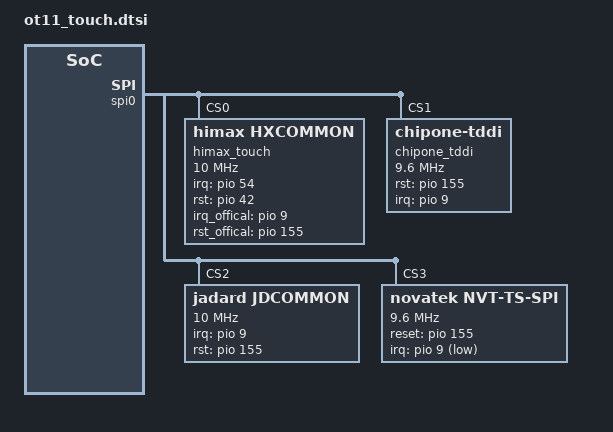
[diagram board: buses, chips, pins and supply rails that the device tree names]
// SPDX-License-Identifier: (GPL-2.0 OR MIT)
/*
 * Copyright (C) 2020 MediaTek Inc.
 */

/* TOUCH start */
/*Tab A9 code for AX6739A-6 by wenghailong at 20230418 start*/
&spi0 {
    status = "okay";
    #address-cells = <1>;
    #size-cells = <0>;
    mediatek,pad-select = <0>;
    cs-gpios = <0>, <0>, <0>, <0>;

    himax_touch@0 {
        compatible = "himax,hxcommon";
        reg = <0>;
        status = "okay";
        spi-max-frequency = <10000000>;
        spi-cpha;
        interrupt-parent = <&pio>;
        himax,panel-coords = <0 800 0 1340>;
        himax,display-coords = <0 800 0 1340>;
        himax,irq-gpio = <&pio 54 0x00>;
        himax,rst-gpio = <&pio 42 0x00>;
        /*Tab A9 code for SR-AX6739A-01-282 by wenghailong at 20230502 start*/
        himax,irq_offical-gpio = <&pio 9 0x00>;
        himax,rst_offical-gpio = <&pio 155 0x00>;
        /*Tab A9 code for SR-AX6739A-01-282 by wenghailong at 20230502 end*/
        report_type = <1>;
    };
    /*Tab A9 code for SR-AX6739A-01-713 by suyurui at 20230601 start*/
    chipone_tddi@1 {
        compatible = "chipone-tddi";
        reg = <1>;
        spi-max-frequency = <9600000>;
        interrupt-parent = <&pio>;
        interrupts = <9 0x2008>;
        chipone,rst-gpio = <&pio 155 0x00>;
        chipone,irq-gpio = <&pio 9 0x00>;
        //chipone,cs-gpio = <&pio 8 0>;
        chipone,x-res = <800>;
        chipone,y-res = <1340>;

        /* Charger detect */
        chipone,touch-charger-detect-enable;
        chipone,touch-charger-detect-type = "notify"; /* notify, poll */
        chipone,touch-charger-detect-psy-name = "charger";
        chipone,touch-charger-detect-psp = "POWER_SUPPLY_PROP_ONLINE";
        chipone,touch-charger-detect-psp-poll-interval = <1000>;

        /* Earjack detect */
        chipone,touch-earjack-detect-enable;
        /* MTK:  /sys/bus/platform/drivers/Accdet_Driver/state,
           Sprd: /sys/kernel/headset/state
           QCOM: None, and disable it */
        chipone,touch-earjack-state-filepath = "/sys/bus/platform/drivers/Accdet_Driver/state";
        chipone,touch-earjack-poll-interval = <1000>;

        /*Tab A9 code for AX6739A-961 by suyurui at 20230609 start*/
        /* For tp selftest */
        chipone,test-reset-pin;
        //chipone,test-int-pin;
        chipone,test-rawdata;
        chipone,test-rawdata-frames = <1>;
        chipone,rawdata-min = <1222>;
        chipone,rawdata-max = <2862>;
        chipone,test-noise;
        chipone,test-noise-frames = <50>;
        chipone,noise-max = <130>;
        chipone,test-open;
        chipone,open-min = <2100>;
        chipone,test-short;
        chipone,short-min = <1900>;
        chipone,test-compensate-cap;
        chipone,compensate-cap-min = <1>;
        chipone,compensate-cap-max = <127>;
        /*Tab A9 code for AX6739A-961 by suyurui at 20230609 end*/

    };
    /*Tab A9 code for SR-AX6739A-01-713 by suyurui at 20230601 end*/

    /*Tab A9 code for SR-AX6739A-01-715 by hehaoran5 at 20230609 start*/
    jadard@2 {
        compatible = "jadard,jdcommon";
        reg = <2>;
        status = "okay";
        spi-max-frequency = <10000000>;//10M
        interrupt-parent = <&pio>;
        interrupts = <9 0x00>;
        jadard,panel-sense-nums = <22 36>;
        jadard,panel-coords = <0 800 0 1340>;
        jadard,int-is-edge = <1>;
        jadard,panel-max-points = <10>;
        jadard,irq-gpio = <&pio 9 0x00>;
        jadard,rst-gpio = <&pio 155 0x00>;
    };
    /*Tab A9 code for SR-AX6739A-01-715 by hehaoran5 at 20230609 end*/

    /*Tab A9 code for AX6739A-2660 by zhawei at 20230811 start*/
    /* Novatek device tree node */
    novatek@3 {
        compatible = "novatek,NVT-ts-spi";
        reg = <3>; //Same as CS ID
        status = "ok";

        spi-max-frequency = <9600000>;    //4800000,9600000,15000000,19200000
        novatek,reset-gpio = <&pio 155 0x00>;
        novatek,irq-gpio = <&pio 9 0x2001>;

        /* 525 */
        //novatek,swrst-n8-addr = <0x01F01A>;

        /* 672A, 525B, 675, 526, 672C, 523, 528, 523D */
        novatek,swrst-n8-addr = <0x03F0FE>;
        novatek,spi-rd-fast-addr = <0x03F310>;

        /*Panel setting*/
        novatek,resolution = <800 1340>;
        novatek,max_touch_num = <10>;
        novatek,area-size = <56 112 60>;    //indicator navigation edge
        novatek,fw_name = "novatek_ts_fw.bin", "tsp_novatek/OT11_NT36523D_LC_HSD_FW_V001_2023xxxx.bin";
        novatek,fw_name_mp = "novatek_ts_mp.bin", "tsp_novatek/OT11_NT36523D_LC_HSD_MP_V001_2023xxxx.bin ";
        //novatek,support_ear_detect_mode;
        novatek,enable_settings_aot;

        /* MP */
        novatek,mp-support-dt;

        novatek-mp-criteria-725E@0 {
            #address-cells = <1>;
            #size-cells = <0>;
            compatible = "novatek-mp-criteria-725E";

            /* sec cmd test config */
            open_test_spec = <(-511) 5120>;
            short_test_spec = <10000 14008>;
            diff_test_frame = <50>;
            /* sec cmd fdm test config */
            fdm_x_num = <2>;
            fdm_diff_test_frame = <50>;

            /* MP Config */
            IC_X_CFG_SIZE = <22>;
            IC_Y_CFG_SIZE = <36>;
            IC_KEY_CFG_SIZE = <4>;
            X_Channel = <22>;
            Y_Channel = <36>;
            AIN_X = <0 1 2 3 4 5 6 7 8 9 10 11 12 13 14 15 16 17 18 19 20 21>; // 22 23 24 25 26 27 28 29 30 31>;
            AIN_Y = <0 1 2 3 4 5 6 7 8 9 10 11 12 13 14 15 16 17
                        18 19 20 21 22 23 24 25 26 27 28 29 30 31 32 33 34 35>; // 36 37 38 39
                        //40 41 42 43 44 45 46 47 48 49>;
            AIN_KEY = <0 1 2 0xFF 0xFF 0xFF 0xFF 0xFF>;

            /* MP Criteria */
            PS_Config_Lmt_Short_Rawdata_P = <
                14008 14008 14008 14008 14008 14008 14008 14008 14008 14008 14008 14008 14008 14008 14008 14008 14008 14008 14008 14008 14008 14008
                14008 14008 14008 14008 14008 14008 14008 14008 14008 14008 14008 14008 14008 14008 14008 14008 14008 14008 14008 14008 14008 14008
                14008 14008 14008 14008 14008 14008 14008 14008 14008 14008 14008 14008 14008 14008 14008 14008 14008 14008 14008 14008 14008 14008
                14008 14008 14008 14008 14008 14008 14008 14008 14008 14008 14008 14008 14008 14008 14008 14008 14008 14008 14008 14008 14008 14008
                14008 14008 14008 14008 14008 14008 14008 14008 14008 14008 14008 14008 14008 14008 14008 14008 14008 14008 14008 14008 14008 14008
                14008 14008 14008 14008 14008 14008 14008 14008 14008 14008 14008 14008 14008 14008 14008 14008 14008 14008 14008 14008 14008 14008
                14008 14008 14008 14008 14008 14008 14008 14008 14008 14008 14008 14008 14008 14008 14008 14008 14008 14008 14008 14008 14008 14008
                14008 14008 14008 14008 14008 14008 14008 14008 14008 14008 14008 14008 14008 14008 14008 14008 14008 14008 14008 14008 14008 14008
                14008 14008 14008 14008 14008 14008 14008 14008 14008 14008 14008 14008 14008 14008 14008 14008 14008 14008 14008 14008 14008 14008
                14008 14008 14008 14008 14008 14008 14008 14008 14008 14008 14008 14008 14008 14008 14008 14008 14008 14008 14008 14008 14008 14008
                14008 14008 14008 14008 14008 14008 14008 14008 14008 14008 14008 14008 14008 14008 14008 14008 14008 14008 14008 14008 14008 14008
                14008 14008 14008 14008 14008 14008 14008 14008 14008 14008 14008 14008 14008 14008 14008 14008 14008 14008 14008 14008 14008 14008
                14008 14008 14008 14008 14008 14008 14008 14008 14008 14008 14008 14008 14008 14008 14008 14008 14008 14008 14008 14008 14008 14008
                14008 14008 14008 14008 14008 14008 14008 14008 14008 14008 14008 14008 14008 14008 14008 14008 14008 14008 14008 14008 14008 14008
                14008 14008 14008 14008 14008 14008 14008 14008 14008 14008 14008 14008 14008 14008 14008 14008 14008 14008 14008 14008 14008 14008
                14008 14008 14008 14008 14008 14008 14008 14008 14008 14008 14008 14008 14008 14008 14008 14008 14008 14008 14008 14008 14008 14008
                14008 14008 14008 14008 14008 14008 14008 14008 14008 14008 14008 14008 14008 14008 14008 14008 14008 14008 14008 14008 14008 14008
                14008 14008 14008 14008 14008 14008 14008 14008 14008 14008 14008 14008 14008 14008 14008 14008 14008 14008 14008 14008 14008 14008
                14008 14008 14008 14008 14008 14008 14008 14008 14008 14008 14008 14008 14008 14008 14008 14008 14008 14008 14008 14008 14008 14008
                14008 14008 14008 14008 14008 14008 14008 14008 14008 14008 14008 14008 14008 14008 14008 14008 14008 14008 14008 14008 14008 14008
                14008 14008 14008 14008 14008 14008 14008 14008 14008 14008 14008 14008 14008 14008 14008 14008 14008 14008 14008 14008 14008 14008
                14008 14008 14008 14008 14008 14008 14008 14008 14008 14008 14008 14008 14008 14008 14008 14008 14008 14008 14008 14008 14008 14008
                14008 14008 14008 14008 14008 14008 14008 14008 14008 14008 14008 14008 14008 14008 14008 14008 14008 14008 14008 14008 14008 14008
                14008 14008 14008 14008 14008 14008 14008 14008 14008 14008 14008 14008 14008 14008 14008 14008 14008 14008 14008 14008 14008 14008
                14008 14008 14008 14008 14008 14008 14008 14008 14008 14008 14008 14008 14008 14008 14008 14008 14008 14008 14008 14008 14008 14008
                14008 14008 14008 14008 14008 14008 14008 14008 14008 14008 14008 14008 14008 14008 14008 14008 14008 14008 14008 14008 14008 14008
                14008 14008 14008 14008 14008 14008 14008 14008 14008 14008 14008 14008 14008 14008 14008 14008 14008 14008 14008 14008 14008 14008
                14008 14008 14008 14008 14008 14008 14008 14008 14008 14008 14008 14008 14008 14008 14008 14008 14008 14008 14008 14008 14008 14008
                14008 14008 14008 14008 14008 14008 14008 14008 14008 14008 14008 14008 14008 14008 14008 14008 14008 14008 14008 14008 14008 14008
                14008 14008 14008 14008 14008 14008 14008 14008 14008 14008 14008 14008 14008 14008 14008 14008 14008 14008 14008 14008 14008 14008
                14008 14008 14008 14008 14008 14008 14008 14008 14008 14008 14008 14008 14008 14008 14008 14008 14008 14008 14008 14008 14008 14008
                14008 14008 14008 14008 14008 14008 14008 14008 14008 14008 14008 14008 14008 14008 14008 14008 14008 14008 14008 14008 14008 14008
                14008 14008 14008 14008 14008 14008 14008 14008 14008 14008 14008 14008 14008 14008 14008 14008 14008 14008 14008 14008 14008 14008
                14008 14008 14008 14008 14008 14008 14008 14008 14008 14008 14008 14008 14008 14008 14008 14008 14008 14008 14008 14008 14008 14008
                14008 14008 14008 14008 14008 14008 14008 14008 14008 14008 14008 14008 14008 14008 14008 14008 14008 14008 14008 14008 14008 14008
                14008 14008 14008 14008 14008 14008 14008 14008 14008 14008 14008 14008 14008 14008 14008 14008 14008 14008 14008 14008 14008 14008
                14008 14008 14008>;

            PS_Config_Lmt_Short_Rawdata_N = <
                10100    10100    10100    10100    10100    10100    10100    10100    10100    10100    10100    10100    10100    10100    10100    10100    10100    10100    10100    10100    10100    10100
                10100    10100    10100    10100    10100    10100    10100    10100    10100    10100    10100    10100    10100    10100    10100    10100    10100    10100    10100    10100    10100    10100
                10100    10100    10100    10100    10100    10100    10100    10100    10100    10100    10100    10100    10100    10100    10100    10100    10100    10100    10100    10100    10100    10100
                10100    10100    10100    10100    10100    10100    10100    10100    10100    10100    10100    10100    10100    10100    10100    10100    10100    10100    10100    10100    10100    10100
                10100    10100    10100    10100    10100    10100    10100    10100    10100    10100    10100    10100    10100    10100    10100    10100    10100    10100    10100    10100    10100    10100
                10100    10100    10100    10100    10100    10100    10100    10100    10100    10100    10100    10100    10100    10100    10100    10100    10100    10100    10100    10100    10100    10100
                10100    10100    10100    10100    10100    10100    10100    10100    10100    10100    10100    10100    10100    10100    10100    10100    10100    10100    10100    10100    10100    10100
                10100    10100    10100    10100    10100    10100    10100    10100    10100    10100    10100    10100    10100    10100    10100    10100    10100    10100    10100    10100    10100    10100
                10100    10100    10100    10100    10100    10100    10100    10100    10100    10100    10100    10100    10100    10100    10100    10100    10100    10100    10100    10100    10100    10100
                10100    10100    10100    10100    10100    10100    10100    10100    10100    10100    10100    10100    10100    10100    10100    10100    10100    10100    10100    10100    10100    10100
                10100    10100    10100    10100    10100    10100    10100    10100    10100    10100    10100    10100    10100    10100    10100    10100    10100    10100    10100    10100    10100    10100
                10100    10100    10100    10100    10100    10100    10100    10100    10100    10100    10100    10100    10100    10100    10100    10100    10100    10100    10100    10100    10100    10100
                10100    10100    10100    10100    10100    10100    10100    10100    10100    10100    10100    10100    10100    10100    10100    10100    10100    10100    10100    10100    10100    10100
                10100    10100    10100    10100    10100    10100    10100    10100    10100    10100    10100    10100    10100    10100    10100    10100    10100    10100    10100    10100    10100    10100
                10100    10100    10100    10100    10100    10100    10100    10100    10100    10100    10100    10100    10100    10100    10100    10100    10100    10100    10100    10100    10100    10100
                10100    10100    10100    10100    10100    10100    10100    10100    10100    10100    10100    10100    10100    10100    10100    10100    10100    10100    10100    10100    10100    10100
                10100    10100    10100    10100    10100    10100    10100    10100    10100    10100    10100    10100    10100    10100    10100    10100    10100    10100    10100    10100    10100    10100
                10100    10100    10100    10100    10100    10100    10100    10100    10100    10100    10100    10100    10100    10100    10100    10100    10100    10100    10100    10100    10100    10100
                10100    10100    10100    10100    10100    10100    10100    10100    10100    10100    10100    10100    10100    10100    10100    10100    10100    10100    10100    10100    10100    10100
                10100    10100    10100    10100    10100    10100    10100    10100    10100    10100    10100    10100    10100    10100    10100    10100    10100    10100    10100    10100    10100    10100
                10100    10100    10100    10100    10100    10100    10100    10100    10100    10100    10100    10100    10100    10100    10100    10100    10100    10100    10100    10100    10100    10100
                10100    10100    10100    10100    10100    10100    10100    10100    10100    10100    10100    10100    10100    10100    10100    10100    10100    10100    10100    10100    10100    10100
                10100    10100    10100    10100    10100    10100    10100    10100    10100    10100    10100    10100    10100    10100    10100    10100    10100    10100    10100    10100    10100    10100
                10100    10100    10100    10100    10100    10100    10100    10100    10100    10100    10100    10100    10100    10100    10100    10100    10100    10100    10100    10100    10100    10100
                10100    10100    10100    10100    10100    10100    10100    10100    10100    10100    10100    10100    10100    10100    10100    10100    10100    10100    10100    10100    10100    10100
                10100    10100    10100    10100    10100    10100    10100    10100    10100    10100    10100    10100    10100    10100    10100    10100    10100    10100    10100    10100    10100    10100
                10100    10100    10100    10100    10100    10100    10100    10100    10100    10100    10100    10100    10100    10100    10100    10100    10100    10100    10100    10100    10100    10100
                10100    10100    10100    10100    10100    10100    10100    10100    10100    10100    10100    10100    10100    10100    10100    10100    10100    10100    10100    10100    10100    10100
                10100    10100    10100    10100    10100    10100    10100    10100    10100    10100    10100    10100    10100    10100    10100    10100    10100    10100    10100    10100    10100    10100
                10100    10100    10100    10100    10100    10100    10100    10100    10100    10100    10100    10100    10100    10100    10100    10100    10100    10100    10100    10100    10100    10100
                10100    10100    10100    10100    10100    10100    10100    10100    10100    10100    10100    10100    10100    10100    10100    10100    10100    10100    10100    10100    10100    10100
                10100    10100    10100    10100    10100    10100    10100    10100    10100    10100    10100    10100    10100    10100    10100    10100    10100    10100    10100    10100    10100    10100
                10100    10100    10100    10100    10100    10100    10100    10100    10100    10100    10100    10100    10100    10100    10100    10100    10100    10100    10100    10100    10100    10100
                10100    10100    10100    10100    10100    10100    10100    10100    10100    10100    10100    10100    10100    10100    10100    10100    10100    10100    10100    10100    10100    10100
                10100    10100    10100    10100    10100    10100    10100    10100    10100    10100    10100    10100    10100    10100    10100    10100    10100    10100    10100    10100    10100    10100
                10100    10100    10100    10100    10100    10100    10100    10100    10100    10100    10100    10100    10100    10100    10100    10100    10100    10100    10100    10100    10100    10100
                10000 10000 10000>;

            PS_Config_Lmt_Open_Rawdata_P = <
                2328    2321    2366    2373    2423    2411    2346    2359    2297    2313    2478    2324    2356    2345    2334    2369    2362    2330    2323    2310    2290    2612
                2388    2295    2398    2426    2397    2391    2342    2328    2320    2345    2514    2299    2342    2349    2374    2362    2356    2349    2321    2327    2324    2582
                2379    2317    2415    2429    2447    2426    2372    2348    2346    2310    2503    2310    2400    2386    2380    2377    2384    2345    2339    2352    2309    2617
                2439    2335    2411    2451    2456    2394    2384    2351    2351    2374    2576    2324    2376    2395    2401    2401    2383    2401    2367    2355    2367    2626
                2429    2359    2355    2467    2461    2460    2450    2404    2426    2372    2577    2345    2355    2442    2422    2409    2437    2429    2390    2388    2386    2643
                2489    2412    2338    2496    2531    2451    2444    2409    2400    2398    2628    2394    2339    2443    2442    2456    2440    2433    2419    2400    2401    2695
                2464    2416    2369    2519    2534    2499    2484    2442    2430    2437    2598    2387    2356    2503    2482    2468    2456    2463    2421    2415    2439    2668
                2520    2475    2388    2524    2559    2512    2457    2454    2433    2444    2660    2432    2374    2485    2489    2492    2491    2465    2474    2451    2437    2727
                2521    2477    2414    2415    2575    2526    2526    2526    2482    2523    2654    2460    2397    2418    2545    2519    2498    2519    2510    2477    2471    2740
                2547    2534    2468    2397    2611    2598    2527    2535    2498    2499    2691    2482    2454    2400    2551    2541    2548    2527    2516    2507    2488    2765
                2589    2517    2482    2439    2639    2611    2576    2575    2528    2531    2731    2530    2449    2416    2607    2580    2561    2541    2540    2512    2493    2801
                2593    2572    2535    2461    2646    2647    2587    2554    2551    2538    2734    2524    2498    2433    2594    2586    2590    2579    2554    2559    2537    2785
                2659    2584    2549    2492    2486    2666    2605    2607    2626    2583    2815    2563    2526    2472    2492    2652    2610    2593    2608    2593    2551    2831
                2642    2607    2600    2538    2470    2699    2670    2617    2624    2600    2787    2573    2542    2519    2475    2646    2633    2640    2608    2597    2576    2845
                2656    2638    2580    2554    2509    2737    2689    2649    2660    2625    2804    2584    2589    2512    2493    2709    2668    2643    2619    2612    2570    2841
                2668    2639    2633    2604    2524    2744    2717    2668    2640    2643    2808    2617    2582    2555    2498    2685    2674    2675    2657    2625    2605    2887
                2692    2703    2643    2618    2554    2555    2727    2689    2684    2716    2856    2654    2621    2579    2540    2559    2738    2691    2670    2668    2610    2899
                2698    2678    2664    2661    2597    2528    2768    2747    2703    2708    2871    2688    2625    2598    2584    2541    2731    2713    2719    2666    2615    2932
                2730    2698    2708    2640    2610    2572    2799    2768    2724    2748    2898    2670    2640    2647    2575    2565    2789    2754    2723    2667    2632    2919
                2754    2699    2705    2695    2664    2580    2817    2796    2757    2731    2913    2712    2670    2640    2622    2572    2766    2759    2755    2710    2647    2974
                2822    2724    2782    2710    2681    2615    2614    2800    2778    2776    2968    2751    2701    2671    2645    2611    2631    2821    2766    2712    2689    2974
                2813    2731    2757    2731    2730    2657    2593    2845    2828    2792    2961    2751    2740    2682    2668    2656    2617    2814    2783    2759    2694    2972
                2853    2748    2780    2773    2705    2664    2628    2874    2846    2807    3013    2794    2724    2695    2713    2646    2638    2874    2818    2755    2691    3007
                2825    2772    2787    2772    2762    2733    2643    2895    2870    2845    2995    2803    2766    2727    2710    2692    2642    2846    2822    2790    2733    3013
                2873    2832    2842    2849    2773    2737    2678    2670    2880    2866    3035    2843    2807    2761    2724    2710    2684    2702    2874    2785    2729    3063
                2880    2815    2843    2820    2800    2792    2720    2646    2919    2908    3044    2835    2800    2799    2745    2734    2727    2689    2859    2799    2775    3066
                2905    2852    2866    2831    2828    2755    2712    2674    2943    2919    3048    2850    2835    2780    2754    2773    2715    2706    2904    2834    2775    3060
                2939    2817    2884    2836    2829    2814    2778    2687    2950    2934    3083    2885    2839    2808    2779    2769    2762    2708    2873    2829    2801    3101
                2967    2901    2976    2940    2946    2871    2828    2762    2748    3000    3161    2951    2941    2898    2856    2820    2813    2790    2803    2922    2838    3142
                3041    2906    2965    2933    2916    2883    2874    2811    2724    3044    3196    2982    2926    2885    2892    2845    2831    2834    2796    2905    2852    3195
                3052    2936    3004    2978    2940    2926    2859    2806    2750    3059    3213    2996    2948    2937    2884    2867    2878    2821    2815    2967    2885    3195
                3087    2974    2989    3007    2951    2932    2909    2870    2775    3077    3234    3030    2990    2940    2916    2898    2884    2880    2831    2944    2895    3235
                3104    2964    3032    3066    3004    3004    2926    2876    2803    2951    3248    3025    3004    2996    2971    2930    2894    2895    2870    2887    2947    3234
                3150    3035    3039    3052    3002    2982    2943    2919    2853    2936    3294    3058    3042    2995    2971    2978    2934    2912    2918    2884    2932    3245
                3171    3045    3066    3098    3049    3000    2975    2906    2848    2950    3300    3104    3051    3004    2999    2964    2946    2960    2902    2905    2990    3291
                3179    3076    3093    3069    3065    3007    2976    2967    2943    3032    3279    3062    3074    3046    3021    3013    2995    2978    2971    2937    2981    3298
                5120 5120 5120>;

            PS_Config_Lmt_Open_Rawdata_N = <
                998    995    1014    1017    1039    1033    1006    1011    985    991    1062    996    1010    1005    1000    1015    1012    998    995    990    982    1120
                1024    983    1028    1040    1027    1025    1004    998    994    1005    1078    985    1004    1007    1018    1012    1010    1007    995    997    996    1106
                1019    993    1035    1041    1049    1040    1016    1006    1006    990    1073    990    1028    1022    1020    1019    1022    1005    1003    1008    989    1121
                1045    1001    1033    1051    1052    1026    1022    1007    1007    1018    1104    996    1018    1027    1029    1029    1021    1029    1015    1009    1015    1126
                1041    1011    1009    1057    1055    1054    1050    1030    1040    1016    1105    1005    1009    1046    1038    1033    1045    1041    1024    1024    1022    1133
                1067    1034    1002    1070    1085    1051    1048    1033    1028    1028    1126    1026    1003    1047    1046    1052    1046    1043    1037    1028    1029    1155
                1056    1036    1015    1079    1086    1071    1064    1046    1042    1045    1114    1023    1010    1073    1064    1058    1052    1055    1037    1035    1045    1144
                1080    1061    1024    1082    1097    1076    1053    1052    1043    1048    1140    1042    1018    1065    1067    1068    1067    1057    1060    1051    1045    1169
                1081    1061    1034    1035    1103    1082    1082    1082    1064    1081    1138    1054    1027    1036    1091    1079    1070    1079    1076    1061    1059    1174
                1091    1086    1058    1027    1119    1114    1083    1087    1070    1071    1153    1064    1052    1028    1093    1089    1092    1083    1078    1075    1066    1185
                1109    1079    1064    1045    1131    1119    1104    1103    1084    1085    1171    1084    1049    1036    1117    1106    1097    1089    1088    1076    1069    1201
                1111    1102    1087    1055    1134    1135    1109    1094    1093    1088    1172    1082    1070    1043    1112    1108    1110    1105    1094    1097    1087    1193
                1139    1108    1093    1068    1066    1142    1117    1117    1126    1107    1207    1099    1082    1060    1068    1136    1118    1111    1118    1111    1093    1213
                1132    1117    1114    1088    1058    1157    1144    1121    1124    1114    1195    1103    1090    1079    1061    1134    1129    1132    1118    1113    1104    1219
                1138    1130    1106    1094    1075    1173    1153    1135    1140    1125    1202    1108    1109    1076    1069    1161    1144    1133    1123    1120    1102    1217
                1144    1131    1129    1116    1082    1176    1165    1144    1132    1133    1204    1121    1106    1095    1070    1151    1146    1147    1139    1125    1117    1237
                1154    1159    1133    1122    1094    1095    1169    1153    1150    1164    1224    1138    1123    1105    1088    1097    1174    1153    1144    1144    1118    1243
                1156    1148    1142    1141    1113    1084    1186    1177    1159    1160    1231    1152    1125    1114    1108    1089    1171    1163    1165    1142    1121    1256
                1170    1156    1160    1132    1118    1102    1199    1186    1168    1178    1242    1144    1132    1135    1103    1099    1195    1180    1167    1143    1128    1251
                1180    1157    1159    1155    1142    1106    1207    1198    1181    1171    1249    1162    1144    1132    1124    1102    1186    1183    1181    1162    1135    1274
                1210    1168    1192    1162    1149    1121    1120    1200    1190    1190    1272    1179    1157    1145    1133    1119    1127    1209    1186    1162    1153    1274
                1205    1171    1181    1171    1170    1139    1111    1219    1212    1196    1269    1179    1174    1150    1144    1138    1121    1206    1193    1183    1154    1274
                1223    1178    1192    1189    1159    1142    1126    1232    1220    1203    1291    1198    1168    1155    1163    1134    1130    1232    1208    1181    1153    1289
                1211    1188    1195    1188    1184    1171    1133    1241    1230    1219    1283    1201    1186    1169    1162    1154    1132    1220    1210    1196    1171    1291
                1231    1214    1218    1221    1189    1173    1148    1144    1234    1228    1301    1219    1203    1183    1168    1162    1150    1158    1232    1193    1169    1313
                1234    1207    1219    1208    1200    1196    1166    1134    1251    1246    1304    1215    1200    1199    1177    1172    1169    1153    1225    1199    1189    1314
                1245    1222    1228    1213    1212    1181    1162    1146    1261    1251    1306    1222    1215    1192    1180    1189    1163    1160    1244    1214    1189    1312
                1259    1207    1236    1216    1213    1206    1190    1151    1264    1258    1321    1237    1217    1204    1191    1187    1184    1160    1231    1213    1201    1329
                1271    1243    1276    1260    1262    1231    1212    1184    1178    1286    1355    1265    1261    1242    1224    1208    1205    1196    1201    1252    1216    1346
                1303    1246    1271    1257    1250    1235    1232    1205    1168    1304    1370    1278    1254    1237    1240    1219    1213    1214    1198    1245    1222    1369
                1308    1258    1288    1276    1260    1254    1225    1202    1178    1311    1377    1284    1264    1259    1236    1229    1234    1209    1207    1271    1237    1369
                1323    1274    1281    1289    1265    1256    1247    1230    1189    1319    1386    1298    1282    1260    1250    1242    1236    1234    1213    1262    1241    1387
                1330    1270    1300    1314    1288    1288    1254    1232    1201    1265    1392    1297    1288    1284    1273    1256    1240    1241    1230    1237    1263    1386
                1350    1301    1303    1308    1286    1278    1261    1251    1223    1258    1412    1310    1304    1283    1273    1276    1258    1248    1250    1236    1256    1391
                1359    1305    1314    1328    1307    1286    1275    1246    1220    1264    1414    1330    1307    1288    1285    1270    1262    1268    1244    1245    1282    1411
                1363    1318    1325    1315    1313    1289    1276    1271    1261    1300    1405    1312    1318    1306    1295    1291    1283    1276    1273    1259    1277    1414
                (-511) (-511) (-511)>;

            PS_Config_Lmt_FW_Rawdata_P = <
                1120    1102    1107    1120    1116    1134    1114    1110    1121    1121    1133    1121    1113    1109    1127    1121    1124    1113    1134    1112    1124    1138
                1114    1105    1124    1116    1127    1123    1134    1114    1137    1113    1133    1131    1119    1126    1120    1114    1130    1119    1110    1121    1124    1127
                1112    1130    1114    1110    1116    1120    1117    1103    1112    1109    1127    1113    1114    1126    1128    1106    1114    1112    1123    1120    1113    1120
                1114    1117    1110    1105    1113    1124    1119    1112    1117    1119    1116    1117    1123    1117    1123    1116    1113    1121    1103    1117    1117    1109
                1113    1106    1120    1131    1102    1130    1127    1120    1121    1140    1112    1119    1107    1120    1130    1114    1133    1109    1120    1109    1114    1127
                1116    1112    1120    1121    1116    1128    1123    1117    1114    1117    1119    1130    1112    1106    1124    1110    1110    1134    1126    1124    1114    1121
                1123    1114    1107    1114    1106    1116    1130    1112    1119    1114    1113    1124    1112    1112    1121    1119    1117    1113    1123    1106    1114    1119
                1112    1120    1119    1107    1114    1119    1116    1127    1117    1113    1123    1121    1114    1124    1120    1116    1120    1128    1114    1135    1124    1109
                1128    1117    1121    1119    1123    1114    1131    1119    1124    1126    1131    1128    1116    1133    1119    1114    1114    1102    1114    1116    1128    1123
                1105    1112    1131    1116    1123    1121    1131    1107    1113    1112    1119    1121    1113    1113    1124    1123    1127    1121    1123    1120    1112    1109
                1120    1112    1123    1134    1113    1120    1124    1106    1133    1127    1116    1116    1119    1121    1121    1123    1117    1116    1112    1133    1117    1123
                1141    1113    1106    1113    1128    1114    1119    1121    1116    1112    1127    1119    1126    1120    1109    1124    1114    1123    1124    1110    1113    1114
                1128    1134    1120    1130    1112    1121    1121    1119    1112    1105    1107    1110    1119    1116    1124    1116    1121    1110    1116    1119    1119    1109
                1112    1124    1120    1107    1106    1114    1121    1134    1120    1112    1140    1117    1131    1112    1109    1123    1121    1127    1112    1123    1116    1128
                1140    1112    1137    1134    1121    1117    1110    1121    1130    1110    1112    1124    1112    1106    1113    1107    1110    1116    1119    1112    1123    1117
                1110    1133    1120    1126    1114    1113    1119    1121    1114    1127    1126    1113    1103    1107    1123    1117    1131    1112    1127    1120    1105    1127
                1124    1124    1116    1113    1109    1120    1144    1123    1127    1109    1130    1116    1117    1116    1140    1113    1119    1121    1114    1121    1119    1134
                1119    1107    1116    1124    1126    1126    1112    1124    1127    1128    1116    1123    1117    1128    1123    1112    1107    1107    1100    1106    1127    1124
                1119    1121    1127    1119    1112    1120    1124    1107    1131    1116    1123    1121    1135    1126    1121    1110    1116    1116    1113    1124    1112    1126
                1142    1114    1112    1110    1116    1121    1130    1119    1117    1116    1121    1128    1117    1120    1126    1127    1127    1109    1121    1123    1130    1116
                1130    1117    1105    1113    1123    1123    1114    1124    1128    1119    1134    1126    1126    1128    1110    1119    1113    1119    1113    1114    1119    1133
                1109    1117    1137    1119    1110    1124    1110    1126    1116    1116    1110    1137    1117    1113    1126    1130    1123    1116    1117    1093    1110    1131
                1106    1126    1106    1109    1127    1117    1117    1106    1128    1112    1123    1128    1120    1105    1119    1121    1121    1124    1121    1117    1119    1106
                1128    1138    1123    1120    1131    1109    1123    1107    1124    1131    1117    1131    1109    1117    1131    1128    1117    1120    1113    1124    1120    1128
                1124    1120    1120    1127    1119    1103    1116    1123    1109    1110    1107    1128    1117    1117    1120    1126    1096    1114    1113    1124    1117    1112
                1124    1103    1116    1102    1119    1128    1117    1127    1116    1113    1117    1126    1112    1119    1116    1120    1123    1119    1123    1119    1103    1109
                1114    1126    1126    1127    1121    1114    1112    1120    1128    1127    1126    1113    1123    1113    1113    1114    1123    1128    1117    1114    1113    1116
                1123    1119    1114    1123    1123    1119    1120    1110    1126    1107    1124    1117    1112    1107    1123    1127    1121    1119    1116    1114    1124    1128
                1124    1113    1124    1123    1123    1114    1124    1112    1127    1133    1128    1124    1124    1106    1114    1114    1137    1112    1114    1113    1127    1127
                1113    1117    1112    1114    1126    1114    1109    1123    1120    1123    1099    1137    1121    1113    1117    1124    1116    1121    1121    1121    1119    1113
                1117    1120    1120    1124    1103    1112    1123    1121    1120    1120    1117    1106    1116    1110    1123    1116    1113    1119    1127    1110    1112    1120
                1124    1131    1120    1127    1107    1124    1121    1128    1127    1126    1116    1116    1127    1103    1109    1120    1137    1114    1123    1109    1119    1126
                1119    1124    1127    1123    1123    1117    1124    1117    1109    1117    1119    1120    1126    1126    1113    1117    1106    1128    1109    1117    1116    1124
                1117    1116    1119    1112    1126    1133    1123    1109    1117    1127    1131    1095    1124    1117    1130    1114    1110    1112    1117    1120    1114    1110
                1112    1106    1112    1123    1119    1112    1110    1126    1106    1121    1126    1119    1135    1117    1124    1123    1114    1105    1110    1123    1121    1120
                1120    1120    1127    1119    1107    1119    1131    1117    1126    1124    1123    1123    1110    1124    1102    1114    1121    1110    1117    1114    1114    1116
                3840 3840 3840>;

            PS_Config_Lmt_FW_Rawdata_N = <
                480    472    475    480    478    486    478    476    481    481    485    481    477    475    483    481    482    477    486    476    482    488
                478    473    482    478    483    481    486    478    487    477    485    485    479    482    480    478    484    479    476    481    482    483
                476    484    478    476    478    480    479    473    476    475    483    477    478    482    484    474    478    476    481    480    477    480
                478    479    476    473    477    482    479    476    479    479    478    479    481    479    481    478    477    481    473    479    479    475
                477    474    480    485    472    484    483    480    481    488    476    479    475    480    484    478    485    475    480    475    478    483
                478    476    480    481    478    484    481    479    478    479    479    484    476    474    482    476    476    486    482    482    478    481
                481    478    475    478    474    478    484    476    479    478    477    482    476    476    481    479    479    477    481    474    478    479
                476    480    479    475    478    479    478    483    479    477    481    481    478    482    480    478    480    484    478    487    482    475
                484    479    481    479    481    478    485    479    482    482    485    484    478    485    479    478    478    472    478    478    484    481
                473    476    485    478    481    481    485    475    477    476    479    481    477    477    482    481    483    481    481    480    476    475
                480    476    481    486    477    480    482    474    485    483    478    478    479    481    481    481    479    478    476    485    479    481
                489    477    474    477    484    478    479    481    478    476    483    479    482    480    475    482    478    481    482    476    477    478
                484    486    480    484    476    481    481    479    476    473    475    476    479    478    482    478    481    476    478    479    479    475
                476    482    480    475    474    478    481    486    480    476    488    479    485    476    475    481    481    483    476    481    478    484
                488    476    487    486    481    479    476    481    484    476    476    482    476    474    477    475    476    478    479    476    481    479
                476    485    480    482    478    477    479    481    478    483    482    477    473    475    481    479    485    476    483    480    473    483
                482    482    478    477    475    480    490    481    483    475    484    478    479    478    488    477    479    481    478    481    479    486
                479    475    478    482    482    482    476    482    483    484    478    481    479    484    481    476    475    475    472    474    483    482
                479    481    483    479    476    480    482    475    485    478    481    481    487    482    481    476    478    478    477    482    476    482
                490    478    476    476    478    481    484    479    479    478    481    484    479    480    482    483    483    475    481    481    484    478
                484    479    473    477    481    481    478    482    484    479    486    482    482    484    476    479    477    479    477    478    479    485
                475    479    487    479    476    482    476    482    478    478    476    487    479    477    482    484    481    478    479    469    476    485
                474    482    474    475    483    479    479    474    484    476    481    484    480    473    479    481    481    482    481    479    479    474
                484    488    481    480    485    475    481    475    482    485    479    485    475    479    485    484    479    480    477    482    480    484
                482    480    480    483    479    473    478    481    475    476    475    484    479    479    480    482    470    478    477    482    479    476
                482    473    478    472    479    484    479    483    478    477    479    482    476    479    478    480    481    479    481    479    473    475
                478    482    482    483    481    478    476    480    484    483    482    477    481    477    477    478    481    484    479    478    477    478
                481    479    478    481    481    479    480    476    482    475    482    479    476    475    481    483    481    479    478    478    482    484
                482    477    482    481    481    478    482    476    483    485    484    482    482    474    478    478    487    476    478    477    483    483
                477    479    476    478    482    478    475    481    480    481    471    487    481    477    479    482    478    481    481    481    479    477
                479    480    480    482    473    476    481    481    480    480    479    474    478    476    481    478    477    479    483    476    476    480
                482    485    480    483    475    482    481    484    483    482    478    478    483    473    475    480    487    478    481    475    479    482
                479    482    483    481    481    479    482    479    475    479    479    480    482    482    477    479    474    484    475    479    478    482
                479    478    479    476    482    485    481    475    479    483    485    469    482    479    484    478    476    476    479    480    478    476
                476    474    476    481    479    476    476    482    474    481    482    479    487    479    482    481    478    473    476    481    481    480
                480    480    483    479    475    479    485    479    482    482    481    481    476    482    472    478    481    476    479    478    478    478
                240 240 240>;

            PS_Config_Lmt_FW_CC_P = <
                91    83    112    112    113    113    113    113    112    112    91    83    115    113    112    113    113    112    112    113    91    80
                90    79    110    112    110    109    110    109    110    110    90    80    110    110    112    110    110    110    110    110    90    79
                87    79    110    109    110    110    110    109    110    109    88    79    113    110    109    109    110    109    109    109    88    77
                101    79    110    112    112    110    110    110    110    112    102    80    112    110    112    112    110    112    110    110    102    79
                109    88    80    109    110    110    110    110    110    109    109    90    80    112    110    110    110    112    110    110    110    87
                112    91    79    112    113    110    110    112    110    112    112    92    80    112    112    113    112    112    112    110    110    90
                109    90    79    112    110    112    112    112    110    110    110    90    80    115    112    110    110    112    110    110    110    88
                112    102    79    112    113    112    112    112    112    112    113    104    81    113    112    113    113    112    112    112    110    102
                109    110    90    80    110    110    112    112    112    112    110    112    90    80    113    112    112    112    112    110    110    110
                112    112    91    80    113    113    112    112    113    112    113    113    92    81    113    112    113    112    112    112    112    110
                110    110    90    80    113    112    112    113    112    112    112    112    91    80    115    112    110    110    113    110    110    109
                110    113    104    80    113    113    113    112    112    112    112    113    104    81    113    112    113    113    112    113    112    110
                112    110    110    90    80    112    112    113    113    113    113    113    112    90    80    113    112    112    112    112    110    110
                110    113    113    92    80    113    115    113    112    113    112    113    113    92    81    113    113    113    112    112    112    110
                110    112    110    90    80    115    112    113    113    113    113    112    112    91    80    115    112    112    112    113    110    110
                112    112    113    104    80    115    115    115    113    113    113    113    113    104    81    115    112    113    113    112    113    112
                112    113    110    112    91    81    112    112    113    113    113    113    113    112    91    81    113    112    112    112    112    110
                112    112    113    113    92    81    115    115    113    113    115    115    113    113    94    81    113    113    113    112    112    112
                112    112    112    110    91    80    115    113    113    115    113    112    112    112    91    81    116    113    112    112    113    110
                112    113    113    115    105    81    115    116    115    113    113    115    113    113    105    83    115    113    115    113    112    112
                112    113    113    112    112    91    81    113    113    115    115    115    113    113    113    91    81    115    113    112    112    112
                112    113    112    113    115    94    81    115    116    115    113    115    115    113    115    94    81    113    113    115    112    112
                112    113    113    113    112    91    81    116    113    115    115    115    113    113    113    91    81    116    113    112    112    113
                112    112    113    113    115    105    81    116    116    116    115    115    116    115    113    105    83    115    113    113    113    112
                113    113    113    115    112    113    92    83    115    113    116    115    115    113    113    113    91    81    115    113    112    112
                112    112    115    113    115    115    94    83    116    117    115    115    115    115    113    115    94    81    113    113    113    112
                112    113    113    113    113    112    92    83    116    113    115    113    116    113    113    113    92    81    116    112    112    112
                113    113    113    115    115    116    106    83    116    116    116    116    115    116    115    113    105    83    115    113    113    113
                112    113    115    115    115    113    113    92    83    115    115    115    115    116    113    113    113    91    81    115    112    112
                115    113    113    115    113    115    116    95    83    116    117    116    115    115    115    113    115    94    81    113    113    113
                112    113    115    115    113    113    113    92    83    116    115    113    115    116    113    113    113    92    81    116    112    112
                115    115    115    113    115    115    116    106    83    117    117    116    116    115    116    115    113    105    83    115    113    113
                112    113    115    115    115    115    113    113    92    83    115    115    115    115    116    113    113    113    91    81    113    112
                115    116    113    113    115    113    115    116    94    83    116    116    116    115    115    115    113    113    94    81    113    113
                115    113    113    115    115    113    113    113    92    83    116    115    113    113    116    113    113    113    92    81    115    112
                115    116    116    115    115    115    115    116    106    83    117    115    116    116    115    116    115    115    106    84    115    113
                314 314 314>;

            PS_Config_Lmt_FW_CC_N = <
                41    37    50    50    51    51    51    51    50    50    41    37    51    51    50    51    51    50    50    51    41    36
                40    35    50    50    50    49    50    49    50    50    40    36    50    50    50    50    50    50    50    50    40    35
                39    35    50    49    50    50    50    49    50    49    40    35    51    50    49    49    50    49    49    49    40    35
                45    35    50    50    50    50    50    50    50    50    46    36    50    50    50    50    50    50    50    50    46    35
                49    40    36    49    50    50    50    50    50    49    49    40    36    50    50    50    50    50    50    50    50    39
                50    41    35    50    51    50    50    50    50    50    50    42    36    50    50    51    50    50    50    50    50    40
                49    40    35    50    50    50    50    50    50    50    50    40    36    51    50    50    50    50    50    50    50    40
                50    46    35    50    51    50    50    50    50    50    51    46    37    51    50    51    51    50    50    50    50    46
                49    50    40    36    50    50    50    50    50    50    50    50    40    36    51    50    50    50    50    50    50    50
                50    50    41    36    51    51    50    50    51    50    51    51    42    37    51    50    51    50    50    50    50    50
                50    50    40    36    51    50    50    51    50    50    50    50    41    36    51    50    50    50    51    50    50    49
                50    51    46    36    51    51    51    50    50    50    50    51    46    37    51    50    51    51    50    51    50    50
                50    50    50    40    36    50    50    51    51    51    51    51    50    40    36    51    50    50    50    50    50    50
                50    51    51    42    36    51    51    51    50    51    50    51    51    42    37    51    51    51    50    50    50    50
                50    50    50    40    36    51    50    51    51    51    51    50    50    41    36    51    50    50    50    51    50    50
                50    50    51    46    36    51    51    51    51    51    51    51    51    46    37    51    50    51    51    50    51    50
                50    51    50    50    41    37    50    50    51    51    51    51    51    50    41    37    51    50    50    50    50    50
                50    50    51    51    42    37    51    51    51    51    51    51    51    51    42    37    51    51    51    50    50    50
                50    50    50    50    41    36    51    51    51    51    51    50    50    50    41    37    52    51    50    50    51    50
                50    51    51    51    47    37    51    52    51    51    51    51    51    51    47    37    51    51    51    51    50    50
                50    51    51    50    50    41    37    51    51    51    51    51    51    51    51    41    37    51    51    50    50    50
                50    51    50    51    51    42    37    51    52    51    51    51    51    51    51    42    37    51    51    51    50    50
                50    51    51    51    50    41    37    52    51    51    51    51    51    51    51    41    37    52    51    50    50    51
                50    50    51    51    51    47    37    52    52    52    51    51    52    51    51    47    37    51    51    51    51    50
                51    51    51    51    50    51    42    37    51    51    52    51    51    51    51    51    41    37    51    51    50    50
                50    50    51    51    51    51    42    37    52    53    51    51    51    51    51    51    42    37    51    51    51    50
                50    51    51    51    51    50    42    37    52    51    51    51    52    51    51    51    42    37    52    50    50    50
                51    51    51    51    51    52    48    37    52    52    52    52    51    52    51    51    47    37    51    51    51    51
                50    51    51    51    51    51    51    42    37    51    51    51    51    52    51    51    51    41    37    51    50    50
                51    51    51    51    51    51    52    43    37    52    53    52    51    51    51    51    51    42    37    51    51    51
                50    51    51    51    51    51    51    42    37    52    51    51    51    52    51    51    51    42    37    52    50    50
                51    51    51    51    51    51    52    48    37    53    53    52    52    51    52    51    51    47    37    51    51    51
                50    51    51    51    51    51    51    51    42    37    51    51    51    51    52    51    51    51    41    37    51    50
                51    52    51    51    51    51    51    52    42    37    52    52    52    51    51    51    51    51    42    37    51    51
                51    51    51    51    51    51    51    51    42    37    52    51    51    51    52    51    51    51    42    37    51    50
                51    52    52    51    51    51    51    52    48    37    53    51    52    52    51    52    51    51    48    38    51    51
                0 0 0>;

            PS_Config_Lmt_FW_Diff_P = <
                50    50    50    50    50    50    50    50    50    50    50    50    50    50    50    50    50    50    50    50    50    50
                50    50    50    50    50    50    50    50    50    50    50    50    50    50    50    50    50    50    50    50    50    50
                50    50    50    50    50    50    50    50    50    50    50    50    50    50    50    50    50    50    50    50    50    50
                50    50    50    50    50    50    50    50    50    50    50    50    50    50    50    50    50    50    50    50    50    50
                50    50    50    50    50    50    50    50    50    50    50    50    50    50    50    50    50    50    50    50    50    50
                50    50    50    50    50    50    50    50    50    50    50    50    50    50    50    50    50    50    50    50    50    50
                50    50    50    50    50    50    50    50    50    50    50    50    50    50    50    50    50    50    50    50    50    50
                50    50    50    50    50    50    50    50    50    50    50    50    50    50    50    50    50    50    50    50    50    50
                50    50    50    50    50    50    50    50    50    50    50    50    50    50    50    50    50    50    50    50    50    50
                50    50    50    50    50    50    50    50    50    50    50    50    50    50    50    50    50    50    50    50    50    50
                50    50    50    50    50    50    50    50    50    50    50    50    50    50    50    50    50    50    50    50    50    50
                50    50    50    50    50    50    50    50    50    50    50    50    50    50    50    50    50    50    50    50    50    50
                50    50    50    50    50    50    50    50    50    50    50    50    50    50    50    50    50    50    50    50    50    50
                50    50    50    50    50    50    50    50    50    50    50    50    50    50    50    50    50    50    50    50    50    50
                50    50    50    50    50    50    50    50    50    50    50    50    50    50    50    50    50    50    50    50    50    50
                50    50    50    50    50    50    50    50    50    50    50    50    50    50    50    50    50    50    50    50    50    50
                50    50    50    50    50    50    50    50    50    50    50    50    50    50    50    50    50    50    50    50    50    50
                50    50    50    50    50    50    50    50    50    50    50    50    50    50    50    50    50    50    50    50    50    50
                50    50    50    50    50    50    50    50    50    50    50    50    50    50    50    50    50    50    50    50    50    50
                50    50    50    50    50    50    50    50    50    50    50    50    50    50    50    50    50    50    50    50    50    50
                50    50    50    50    50    50    50    50    50    50    50    50    50    50    50    50    50    50    50    50    50    50
                50    50    50    50    50    50    50    50    50    50    50    50    50    50    50    50    50    50    50    50    50    50
                50    50    50    50    50    50    50    50    50    50    50    50    50    50    50    50    50    50    50    50    50    50
                50    50    50    50    50    50    50    50    50    50    50    50    50    50    50    50    50    50    50    50    50    50
                50    50    50    50    50    50    50    50    50    50    50    50    50    50    50    50    50    50    50    50    50    50
                50    50    50    50    50    50    50    50    50    50    50    50    50    50    50    50    50    50    50    50    50    50
                50    50    50    50    50    50    50    50    50    50    50    50    50    50    50    50    50    50    50    50    50    50
                50    50    50    50    50    50    50    50    50    50    50    50    50    50    50    50    50    50    50    50    50    50
                50    50    50    50    50    50    50    50    50    50    50    50    50    50    50    50    50    50    50    50    50    50
                50    50    50    50    50    50    50    50    50    50    50    50    50    50    50    50    50    50    50    50    50    50
                50    50    50    50    50    50    50    50    50    50    50    50    50    50    50    50    50    50    50    50    50    50
                50    50    50    50    50    50    50    50    50    50    50    50    50    50    50    50    50    50    50    50    50    50
                50    50    50    50    50    50    50    50    50    50    50    50    50    50    50    50    50    50    50    50    50    50
                50    50    50    50    50    50    50    50    50    50    50    50    50    50    50    50    50    50    50    50    50    50
                50    50    50    50    50    50    50    50    50    50    50    50    50    50    50    50    50    50    50    50    50    50
                50    50    50    50    50    50    50    50    50    50    50    50    50    50    50    50    50    50    50    50    50    50
                75 75 75>;

            PS_Config_Lmt_FW_Diff_N = <
                (-50)    (-50)    (-50)    (-50)    (-50)    (-50)    (-50)    (-50)    (-50)    (-50)    (-50)    (-50)    (-50)    (-50)    (-50)    (-50)    (-50)    (-50)    (-50)    (-50)    (-50)    (-50)
                (-50)    (-50)    (-50)    (-50)    (-50)    (-50)    (-50)    (-50)    (-50)    (-50)    (-50)    (-50)    (-50)    (-50)    (-50)    (-50)    (-50)    (-50)    (-50)    (-50)    (-50)    (-50)
                (-50)    (-50)    (-50)    (-50)    (-50)    (-50)    (-50)    (-50)    (-50)    (-50)    (-50)    (-50)    (-50)    (-50)    (-50)    (-50)    (-50)    (-50)    (-50)    (-50)    (-50)    (-50)
                (-50)    (-50)    (-50)    (-50)    (-50)    (-50)    (-50)    (-50)    (-50)    (-50)    (-50)    (-50)    (-50)    (-50)    (-50)    (-50)    (-50)    (-50)    (-50)    (-50)    (-50)    (-50)
                (-50)    (-50)    (-50)    (-50)    (-50)    (-50)    (-50)    (-50)    (-50)    (-50)    (-50)    (-50)    (-50)    (-50)    (-50)    (-50)    (-50)    (-50)    (-50)    (-50)    (-50)    (-50)
                (-50)    (-50)    (-50)    (-50)    (-50)    (-50)    (-50)    (-50)    (-50)    (-50)    (-50)    (-50)    (-50)    (-50)    (-50)    (-50)    (-50)    (-50)    (-50)    (-50)    (-50)    (-50)
                (-50)    (-50)    (-50)    (-50)    (-50)    (-50)    (-50)    (-50)    (-50)    (-50)    (-50)    (-50)    (-50)    (-50)    (-50)    (-50)    (-50)    (-50)    (-50)    (-50)    (-50)    (-50)
                (-50)    (-50)    (-50)    (-50)    (-50)    (-50)    (-50)    (-50)    (-50)    (-50)    (-50)    (-50)    (-50)    (-50)    (-50)    (-50)    (-50)    (-50)    (-50)    (-50)    (-50)    (-50)
                (-50)    (-50)    (-50)    (-50)    (-50)    (-50)    (-50)    (-50)    (-50)    (-50)    (-50)    (-50)    (-50)    (-50)    (-50)    (-50)    (-50)    (-50)    (-50)    (-50)    (-50)    (-50)
                (-50)    (-50)    (-50)    (-50)    (-50)    (-50)    (-50)    (-50)    (-50)    (-50)    (-50)    (-50)    (-50)    (-50)    (-50)    (-50)    (-50)    (-50)    (-50)    (-50)    (-50)    (-50)
                (-50)    (-50)    (-50)    (-50)    (-50)    (-50)    (-50)    (-50)    (-50)    (-50)    (-50)    (-50)    (-50)    (-50)    (-50)    (-50)    (-50)    (-50)    (-50)    (-50)    (-50)    (-50)
                (-50)    (-50)    (-50)    (-50)    (-50)    (-50)    (-50)    (-50)    (-50)    (-50)    (-50)    (-50)    (-50)    (-50)    (-50)    (-50)    (-50)    (-50)    (-50)    (-50)    (-50)    (-50)
                (-50)    (-50)    (-50)    (-50)    (-50)    (-50)    (-50)    (-50)    (-50)    (-50)    (-50)    (-50)    (-50)    (-50)    (-50)    (-50)    (-50)    (-50)    (-50)    (-50)    (-50)    (-50)
                (-50)    (-50)    (-50)    (-50)    (-50)    (-50)    (-50)    (-50)    (-50)    (-50)    (-50)    (-50)    (-50)    (-50)    (-50)    (-50)    (-50)    (-50)    (-50)    (-50)    (-50)    (-50)
                (-50)    (-50)    (-50)    (-50)    (-50)    (-50)    (-50)    (-50)    (-50)    (-50)    (-50)    (-50)    (-50)    (-50)    (-50)    (-50)    (-50)    (-50)    (-50)    (-50)    (-50)    (-50)
                (-50)    (-50)    (-50)    (-50)    (-50)    (-50)    (-50)    (-50)    (-50)    (-50)    (-50)    (-50)    (-50)    (-50)    (-50)    (-50)    (-50)    (-50)    (-50)    (-50)    (-50)    (-50)
                (-50)    (-50)    (-50)    (-50)    (-50)    (-50)    (-50)    (-50)    (-50)    (-50)    (-50)    (-50)    (-50)    (-50)    (-50)    (-50)    (-50)    (-50)    (-50)    (-50)    (-50)    (-50)
                (-50)    (-50)    (-50)    (-50)    (-50)    (-50)    (-50)    (-50)    (-50)    (-50)    (-50)    (-50)    (-50)    (-50)    (-50)    (-50)    (-50)    (-50)    (-50)    (-50)    (-50)    (-50)
                (-50)    (-50)    (-50)    (-50)    (-50)    (-50)    (-50)    (-50)    (-50)    (-50)    (-50)    (-50)    (-50)    (-50)    (-50)    (-50)    (-50)    (-50)    (-50)    (-50)    (-50)    (-50)
                (-50)    (-50)    (-50)    (-50)    (-50)    (-50)    (-50)    (-50)    (-50)    (-50)    (-50)    (-50)    (-50)    (-50)    (-50)    (-50)    (-50)    (-50)    (-50)    (-50)    (-50)    (-50)
                (-50)    (-50)    (-50)    (-50)    (-50)    (-50)    (-50)    (-50)    (-50)    (-50)    (-50)    (-50)    (-50)    (-50)    (-50)    (-50)    (-50)    (-50)    (-50)    (-50)    (-50)    (-50)
                (-50)    (-50)    (-50)    (-50)    (-50)    (-50)    (-50)    (-50)    (-50)    (-50)    (-50)    (-50)    (-50)    (-50)    (-50)    (-50)    (-50)    (-50)    (-50)    (-50)    (-50)    (-50)
                (-50)    (-50)    (-50)    (-50)    (-50)    (-50)    (-50)    (-50)    (-50)    (-50)    (-50)    (-50)    (-50)    (-50)    (-50)    (-50)    (-50)    (-50)    (-50)    (-50)    (-50)    (-50)
                (-50)    (-50)    (-50)    (-50)    (-50)    (-50)    (-50)    (-50)    (-50)    (-50)    (-50)    (-50)    (-50)    (-50)    (-50)    (-50)    (-50)    (-50)    (-50)    (-50)    (-50)    (-50)
                (-50)    (-50)    (-50)    (-50)    (-50)    (-50)    (-50)    (-50)    (-50)    (-50)    (-50)    (-50)    (-50)    (-50)    (-50)    (-50)    (-50)    (-50)    (-50)    (-50)    (-50)    (-50)
                (-50)    (-50)    (-50)    (-50)    (-50)    (-50)    (-50)    (-50)    (-50)    (-50)    (-50)    (-50)    (-50)    (-50)    (-50)    (-50)    (-50)    (-50)    (-50)    (-50)    (-50)    (-50)
                (-50)    (-50)    (-50)    (-50)    (-50)    (-50)    (-50)    (-50)    (-50)    (-50)    (-50)    (-50)    (-50)    (-50)    (-50)    (-50)    (-50)    (-50)    (-50)    (-50)    (-50)    (-50)
                (-50)    (-50)    (-50)    (-50)    (-50)    (-50)    (-50)    (-50)    (-50)    (-50)    (-50)    (-50)    (-50)    (-50)    (-50)    (-50)    (-50)    (-50)    (-50)    (-50)    (-50)    (-50)
                (-50)    (-50)    (-50)    (-50)    (-50)    (-50)    (-50)    (-50)    (-50)    (-50)    (-50)    (-50)    (-50)    (-50)    (-50)    (-50)    (-50)    (-50)    (-50)    (-50)    (-50)    (-50)
                (-50)    (-50)    (-50)    (-50)    (-50)    (-50)    (-50)    (-50)    (-50)    (-50)    (-50)    (-50)    (-50)    (-50)    (-50)    (-50)    (-50)    (-50)    (-50)    (-50)    (-50)    (-50)
                (-50)    (-50)    (-50)    (-50)    (-50)    (-50)    (-50)    (-50)    (-50)    (-50)    (-50)    (-50)    (-50)    (-50)    (-50)    (-50)    (-50)    (-50)    (-50)    (-50)    (-50)    (-50)
                (-50)    (-50)    (-50)    (-50)    (-50)    (-50)    (-50)    (-50)    (-50)    (-50)    (-50)    (-50)    (-50)    (-50)    (-50)    (-50)    (-50)    (-50)    (-50)    (-50)    (-50)    (-50)
                (-50)    (-50)    (-50)    (-50)    (-50)    (-50)    (-50)    (-50)    (-50)    (-50)    (-50)    (-50)    (-50)    (-50)    (-50)    (-50)    (-50)    (-50)    (-50)    (-50)    (-50)    (-50)
                (-50)    (-50)    (-50)    (-50)    (-50)    (-50)    (-50)    (-50)    (-50)    (-50)    (-50)    (-50)    (-50)    (-50)    (-50)    (-50)    (-50)    (-50)    (-50)    (-50)    (-50)    (-50)
                (-50)    (-50)    (-50)    (-50)    (-50)    (-50)    (-50)    (-50)    (-50)    (-50)    (-50)    (-50)    (-50)    (-50)    (-50)    (-50)    (-50)    (-50)    (-50)    (-50)    (-50)    (-50)
                (-50)    (-50)    (-50)    (-50)    (-50)    (-50)    (-50)    (-50)    (-50)    (-50)    (-50)    (-50)    (-50)    (-50)    (-50)    (-50)    (-50)    (-50)    (-50)    (-50)    (-50)    (-50)
                (-75) (-75) (-75)>;

            PS_Config_Diff_Test_Frame = <50>;

            PS_Config_Lmt_LPWG_Rawdata_P = <
                3840 3840 3840 3840 3840 3840 3840 3840 3840 3840 3840 3840 3840 3840 3840 3840 3840 3840 3840 3840 3840 3840
                3840 3840 3840 3840 3840 3840 3840 3840 3840 3840 3840 3840 3840 3840 3840 3840 3840 3840 3840 3840 3840 3840
                3840 3840 3840 3840 3840 3840 3840 3840 3840 3840 3840 3840 3840 3840 3840 3840 3840 3840 3840 3840 3840 3840
                3840 3840 3840 3840 3840 3840 3840 3840 3840 3840 3840 3840 3840 3840 3840 3840 3840 3840 3840 3840 3840 3840
                3840 3840 3840 3840 3840 3840 3840 3840 3840 3840 3840 3840 3840 3840 3840 3840 3840 3840 3840 3840 3840 3840
                3840 3840 3840 3840 3840 3840 3840 3840 3840 3840 3840 3840 3840 3840 3840 3840 3840 3840 3840 3840 3840 3840
                3840 3840 3840 3840 3840 3840 3840 3840 3840 3840 3840 3840 3840 3840 3840 3840 3840 3840 3840 3840 3840 3840
                3840 3840 3840 3840 3840 3840 3840 3840 3840 3840 3840 3840 3840 3840 3840 3840 3840 3840 3840 3840 3840 3840
                3840 3840 3840 3840 3840 3840 3840 3840 3840 3840 3840 3840 3840 3840 3840 3840 3840 3840 3840 3840 3840 3840
                3840 3840 3840 3840 3840 3840 3840 3840 3840 3840 3840 3840 3840 3840 3840 3840 3840 3840 3840 3840 3840 3840
                3840 3840 3840 3840 3840 3840 3840 3840 3840 3840 3840 3840 3840 3840 3840 3840 3840 3840 3840 3840 3840 3840
                3840 3840 3840 3840 3840 3840 3840 3840 3840 3840 3840 3840 3840 3840 3840 3840 3840 3840 3840 3840 3840 3840
                3840 3840 3840 3840 3840 3840 3840 3840 3840 3840 3840 3840 3840 3840 3840 3840 3840 3840 3840 3840 3840 3840
                3840 3840 3840 3840 3840 3840 3840 3840 3840 3840 3840 3840 3840 3840 3840 3840 3840 3840 3840 3840 3840 3840
                3840 3840 3840 3840 3840 3840 3840 3840 3840 3840 3840 3840 3840 3840 3840 3840 3840 3840 3840 3840 3840 3840
                3840 3840 3840 3840 3840 3840 3840 3840 3840 3840 3840 3840 3840 3840 3840 3840 3840 3840 3840 3840 3840 3840
                3840 3840 3840 3840 3840 3840 3840 3840 3840 3840 3840 3840 3840 3840 3840 3840 3840 3840 3840 3840 3840 3840
                3840 3840 3840 3840 3840 3840 3840 3840 3840 3840 3840 3840 3840 3840 3840 3840 3840 3840 3840 3840 3840 3840
                3840 3840 3840 3840 3840 3840 3840 3840 3840 3840 3840 3840 3840 3840 3840 3840 3840 3840 3840 3840 3840 3840
                3840 3840 3840 3840 3840 3840 3840 3840 3840 3840 3840 3840 3840 3840 3840 3840 3840 3840 3840 3840 3840 3840
                3840 3840 3840 3840 3840 3840 3840 3840 3840 3840 3840 3840 3840 3840 3840 3840 3840 3840 3840 3840 3840 3840
                3840 3840 3840 3840 3840 3840 3840 3840 3840 3840 3840 3840 3840 3840 3840 3840 3840 3840 3840 3840 3840 3840
                3840 3840 3840 3840 3840 3840 3840 3840 3840 3840 3840 3840 3840 3840 3840 3840 3840 3840 3840 3840 3840 3840
                3840 3840 3840 3840 3840 3840 3840 3840 3840 3840 3840 3840 3840 3840 3840 3840 3840 3840 3840 3840 3840 3840
                3840 3840 3840 3840 3840 3840 3840 3840 3840 3840 3840 3840 3840 3840 3840 3840 3840 3840 3840 3840 3840 3840
                3840 3840 3840 3840 3840 3840 3840 3840 3840 3840 3840 3840 3840 3840 3840 3840 3840 3840 3840 3840 3840 3840
                3840 3840 3840 3840 3840 3840 3840 3840 3840 3840 3840 3840 3840 3840 3840 3840 3840 3840 3840 3840 3840 3840
                3840 3840 3840 3840 3840 3840 3840 3840 3840 3840 3840 3840 3840 3840 3840 3840 3840 3840 3840 3840 3840 3840
                3840 3840 3840 3840 3840 3840 3840 3840 3840 3840 3840 3840 3840 3840 3840 3840 3840 3840 3840 3840 3840 3840
                3840 3840 3840 3840 3840 3840 3840 3840 3840 3840 3840 3840 3840 3840 3840 3840 3840 3840 3840 3840 3840 3840
                3840 3840 3840 3840 3840 3840 3840 3840 3840 3840 3840 3840 3840 3840 3840 3840 3840 3840 3840 3840 3840 3840
                3840 3840 3840 3840 3840 3840 3840 3840 3840 3840 3840 3840 3840 3840 3840 3840 3840 3840 3840 3840 3840 3840
                3840 3840 3840 3840 3840 3840 3840 3840 3840 3840 3840 3840 3840 3840 3840 3840 3840 3840 3840 3840 3840 3840
                3840 3840 3840 3840 3840 3840 3840 3840 3840 3840 3840 3840 3840 3840 3840 3840 3840 3840 3840 3840 3840 3840
                3840 3840 3840 3840 3840 3840 3840 3840 3840 3840 3840 3840 3840 3840 3840 3840 3840 3840 3840 3840 3840 3840
                3840 3840 3840 3840 3840 3840 3840 3840 3840 3840 3840 3840 3840 3840 3840 3840 3840 3840 3840 3840 3840 3840
                3840 3840 3840>;

            PS_Config_Lmt_LPWG_Rawdata_N = <
                240 240 240 240 240 240 240 240 240 240 240 240 240 240 240 240 240 240 240 240 240 240
                240 240 240 240 240 240 240 240 240 240 240 240 240 240 240 240 240 240 240 240 240 240
                240 240 240 240 240 240 240 240 240 240 240 240 240 240 240 240 240 240 240 240 240 240
                240 240 240 240 240 240 240 240 240 240 240 240 240 240 240 240 240 240 240 240 240 240
                240 240 240 240 240 240 240 240 240 240 240 240 240 240 240 240 240 240 240 240 240 240
                240 240 240 240 240 240 240 240 240 240 240 240 240 240 240 240 240 240 240 240 240 240
                240 240 240 240 240 240 240 240 240 240 240 240 240 240 240 240 240 240 240 240 240 240
                240 240 240 240 240 240 240 240 240 240 240 240 240 240 240 240 240 240 240 240 240 240
                240 240 240 240 240 240 240 240 240 240 240 240 240 240 240 240 240 240 240 240 240 240
                240 240 240 240 240 240 240 240 240 240 240 240 240 240 240 240 240 240 240 240 240 240
                240 240 240 240 240 240 240 240 240 240 240 240 240 240 240 240 240 240 240 240 240 240
                240 240 240 240 240 240 240 240 240 240 240 240 240 240 240 240 240 240 240 240 240 240
                240 240 240 240 240 240 240 240 240 240 240 240 240 240 240 240 240 240 240 240 240 240
                240 240 240 240 240 240 240 240 240 240 240 240 240 240 240 240 240 240 240 240 240 240
                240 240 240 240 240 240 240 240 240 240 240 240 240 240 240 240 240 240 240 240 240 240
                240 240 240 240 240 240 240 240 240 240 240 240 240 240 240 240 240 240 240 240 240 240
                240 240 240 240 240 240 240 240 240 240 240 240 240 240 240 240 240 240 240 240 240 240
                240 240 240 240 240 240 240 240 240 240 240 240 240 240 240 240 240 240 240 240 240 240
                240 240 240 240 240 240 240 240 240 240 240 240 240 240 240 240 240 240 240 240 240 240
                240 240 240 240 240 240 240 240 240 240 240 240 240 240 240 240 240 240 240 240 240 240
                240 240 240 240 240 240 240 240 240 240 240 240 240 240 240 240 240 240 240 240 240 240
                240 240 240 240 240 240 240 240 240 240 240 240 240 240 240 240 240 240 240 240 240 240
                240 240 240 240 240 240 240 240 240 240 240 240 240 240 240 240 240 240 240 240 240 240
                240 240 240 240 240 240 240 240 240 240 240 240 240 240 240 240 240 240 240 240 240 240
                240 240 240 240 240 240 240 240 240 240 240 240 240 240 240 240 240 240 240 240 240 240
                240 240 240 240 240 240 240 240 240 240 240 240 240 240 240 240 240 240 240 240 240 240
                240 240 240 240 240 240 240 240 240 240 240 240 240 240 240 240 240 240 240 240 240 240
                240 240 240 240 240 240 240 240 240 240 240 240 240 240 240 240 240 240 240 240 240 240
                240 240 240 240 240 240 240 240 240 240 240 240 240 240 240 240 240 240 240 240 240 240
                240 240 240 240 240 240 240 240 240 240 240 240 240 240 240 240 240 240 240 240 240 240
                240 240 240 240 240 240 240 240 240 240 240 240 240 240 240 240 240 240 240 240 240 240
                240 240 240 240 240 240 240 240 240 240 240 240 240 240 240 240 240 240 240 240 240 240
                240 240 240 240 240 240 240 240 240 240 240 240 240 240 240 240 240 240 240 240 240 240
                240 240 240 240 240 240 240 240 240 240 240 240 240 240 240 240 240 240 240 240 240 240
                240 240 240 240 240 240 240 240 240 240 240 240 240 240 240 240 240 240 240 240 240 240
                240 240 240 240 240 240 240 240 240 240 240 240 240 240 240 240 240 240 240 240 240 240
                240 240 240>;

            PS_Config_Lmt_LPWG_Diff_P = <
                75 75 75 75 75 75 75 75 75 75 75 75 75 75 75 75 75 75 75 75 75 75
                75 75 75 75 75 75 75 75 75 75 75 75 75 75 75 75 75 75 75 75 75 75
                75 75 75 75 75 75 75 75 75 75 75 75 75 75 75 75 75 75 75 75 75 75
                75 75 75 75 75 75 75 75 75 75 75 75 75 75 75 75 75 75 75 75 75 75
                75 75 75 75 75 75 75 75 75 75 75 75 75 75 75 75 75 75 75 75 75 75
                75 75 75 75 75 75 75 75 75 75 75 75 75 75 75 75 75 75 75 75 75 75
                75 75 75 75 75 75 75 75 75 75 75 75 75 75 75 75 75 75 75 75 75 75
                75 75 75 75 75 75 75 75 75 75 75 75 75 75 75 75 75 75 75 75 75 75
                75 75 75 75 75 75 75 75 75 75 75 75 75 75 75 75 75 75 75 75 75 75
                75 75 75 75 75 75 75 75 75 75 75 75 75 75 75 75 75 75 75 75 75 75
                75 75 75 75 75 75 75 75 75 75 75 75 75 75 75 75 75 75 75 75 75 75
                75 75 75 75 75 75 75 75 75 75 75 75 75 75 75 75 75 75 75 75 75 75
                75 75 75 75 75 75 75 75 75 75 75 75 75 75 75 75 75 75 75 75 75 75
                75 75 75 75 75 75 75 75 75 75 75 75 75 75 75 75 75 75 75 75 75 75
                75 75 75 75 75 75 75 75 75 75 75 75 75 75 75 75 75 75 75 75 75 75
                75 75 75 75 75 75 75 75 75 75 75 75 75 75 75 75 75 75 75 75 75 75
                75 75 75 75 75 75 75 75 75 75 75 75 75 75 75 75 75 75 75 75 75 75
                75 75 75 75 75 75 75 75 75 75 75 75 75 75 75 75 75 75 75 75 75 75
                75 75 75 75 75 75 75 75 75 75 75 75 75 75 75 75 75 75 75 75 75 75
                75 75 75 75 75 75 75 75 75 75 75 75 75 75 75 75 75 75 75 75 75 75
                75 75 75 75 75 75 75 75 75 75 75 75 75 75 75 75 75 75 75 75 75 75
                75 75 75 75 75 75 75 75 75 75 75 75 75 75 75 75 75 75 75 75 75 75
                75 75 75 75 75 75 75 75 75 75 75 75 75 75 75 75 75 75 75 75 75 75
                75 75 75 75 75 75 75 75 75 75 75 75 75 75 75 75 75 75 75 75 75 75
                75 75 75 75 75 75 75 75 75 75 75 75 75 75 75 75 75 75 75 75 75 75
                75 75 75 75 75 75 75 75 75 75 75 75 75 75 75 75 75 75 75 75 75 75
                75 75 75 75 75 75 75 75 75 75 75 75 75 75 75 75 75 75 75 75 75 75
                75 75 75 75 75 75 75 75 75 75 75 75 75 75 75 75 75 75 75 75 75 75
                75 75 75 75 75 75 75 75 75 75 75 75 75 75 75 75 75 75 75 75 75 75
                75 75 75 75 75 75 75 75 75 75 75 75 75 75 75 75 75 75 75 75 75 75
                75 75 75 75 75 75 75 75 75 75 75 75 75 75 75 75 75 75 75 75 75 75
                75 75 75 75 75 75 75 75 75 75 75 75 75 75 75 75 75 75 75 75 75 75
                75 75 75 75 75 75 75 75 75 75 75 75 75 75 75 75 75 75 75 75 75 75
                75 75 75 75 75 75 75 75 75 75 75 75 75 75 75 75 75 75 75 75 75 75
                75 75 75 75 75 75 75 75 75 75 75 75 75 75 75 75 75 75 75 75 75 75
                75 75 75 75 75 75 75 75 75 75 75 75 75 75 75 75 75 75 75 75 75 75
                75 75 75>;

            PS_Config_Lmt_LPWG_Diff_N = <
                (-75) (-75) (-75) (-75) (-75) (-75) (-75) (-75) (-75) (-75) (-75) (-75) (-75) (-75) (-75) (-75) (-75) (-75) (-75) (-75) (-75) (-75) (-75) (-75) (-75) (-75)
                (-75) (-75) (-75) (-75) (-75) (-75) (-75) (-75) (-75) (-75) (-75) (-75) (-75) (-75) (-75) (-75) (-75) (-75) (-75) (-75) (-75) (-75) (-75) (-75) (-75) (-75)
                (-75) (-75) (-75) (-75) (-75) (-75) (-75) (-75) (-75) (-75) (-75) (-75) (-75) (-75) (-75) (-75) (-75) (-75) (-75) (-75) (-75) (-75) (-75) (-75) (-75) (-75)
                (-75) (-75) (-75) (-75) (-75) (-75) (-75) (-75) (-75) (-75) (-75) (-75) (-75) (-75) (-75) (-75) (-75) (-75) (-75) (-75) (-75) (-75) (-75) (-75) (-75) (-75)
                (-75) (-75) (-75) (-75) (-75) (-75) (-75) (-75) (-75) (-75) (-75) (-75) (-75) (-75) (-75) (-75) (-75) (-75) (-75) (-75) (-75) (-75) (-75) (-75) (-75) (-75)
                (-75) (-75) (-75) (-75) (-75) (-75) (-75) (-75) (-75) (-75) (-75) (-75) (-75) (-75) (-75) (-75) (-75) (-75) (-75) (-75) (-75) (-75) (-75) (-75) (-75) (-75)
                (-75) (-75) (-75) (-75) (-75) (-75) (-75) (-75) (-75) (-75) (-75) (-75) (-75) (-75) (-75) (-75) (-75) (-75) (-75) (-75) (-75) (-75) (-75) (-75) (-75) (-75)
                (-75) (-75) (-75) (-75) (-75) (-75) (-75) (-75) (-75) (-75) (-75) (-75) (-75) (-75) (-75) (-75) (-75) (-75) (-75) (-75) (-75) (-75) (-75) (-75) (-75) (-75)
                (-75) (-75) (-75) (-75) (-75) (-75) (-75) (-75) (-75) (-75) (-75) (-75) (-75) (-75) (-75) (-75) (-75) (-75) (-75) (-75) (-75) (-75) (-75) (-75) (-75) (-75)
                (-75) (-75) (-75) (-75) (-75) (-75) (-75) (-75) (-75) (-75) (-75) (-75) (-75) (-75) (-75) (-75) (-75) (-75) (-75) (-75) (-75) (-75) (-75) (-75) (-75) (-75)
                (-75) (-75) (-75) (-75) (-75) (-75) (-75) (-75) (-75) (-75) (-75) (-75) (-75) (-75) (-75) (-75) (-75) (-75) (-75) (-75) (-75) (-75) (-75) (-75) (-75) (-75)
                (-75) (-75) (-75) (-75) (-75) (-75) (-75) (-75) (-75) (-75) (-75) (-75) (-75) (-75) (-75) (-75) (-75) (-75) (-75) (-75) (-75) (-75) (-75) (-75) (-75) (-75)
                (-75) (-75) (-75) (-75) (-75) (-75) (-75) (-75) (-75) (-75) (-75) (-75) (-75) (-75) (-75) (-75) (-75) (-75) (-75) (-75) (-75) (-75) (-75) (-75) (-75) (-75)
                (-75) (-75) (-75) (-75) (-75) (-75) (-75) (-75) (-75) (-75) (-75) (-75) (-75) (-75) (-75) (-75) (-75) (-75) (-75) (-75) (-75) (-75) (-75) (-75) (-75) (-75)
                (-75) (-75) (-75) (-75) (-75) (-75) (-75) (-75) (-75) (-75) (-75) (-75) (-75) (-75) (-75) (-75) (-75) (-75) (-75) (-75) (-75) (-75) (-75) (-75) (-75) (-75)
                (-75) (-75) (-75) (-75) (-75) (-75) (-75) (-75) (-75) (-75) (-75) (-75) (-75) (-75) (-75) (-75) (-75) (-75) (-75) (-75) (-75) (-75) (-75) (-75) (-75) (-75)
                (-75) (-75) (-75) (-75) (-75) (-75) (-75) (-75) (-75) (-75) (-75) (-75) (-75) (-75) (-75) (-75) (-75) (-75) (-75) (-75) (-75) (-75) (-75) (-75) (-75) (-75)
                (-75) (-75) (-75) (-75) (-75) (-75) (-75) (-75) (-75) (-75) (-75) (-75) (-75) (-75) (-75) (-75) (-75) (-75) (-75) (-75) (-75) (-75) (-75) (-75) (-75) (-75)
                (-75) (-75) (-75) (-75) (-75) (-75) (-75) (-75) (-75) (-75) (-75) (-75) (-75) (-75) (-75) (-75) (-75) (-75) (-75) (-75) (-75) (-75) (-75) (-75) (-75) (-75)
                (-75) (-75) (-75) (-75) (-75) (-75) (-75) (-75) (-75) (-75) (-75) (-75) (-75) (-75) (-75) (-75) (-75) (-75) (-75) (-75) (-75) (-75) (-75) (-75) (-75) (-75)
                (-75) (-75) (-75) (-75) (-75) (-75) (-75) (-75) (-75) (-75) (-75) (-75) (-75) (-75) (-75) (-75) (-75) (-75) (-75) (-75) (-75) (-75) (-75) (-75) (-75) (-75)
                (-75) (-75) (-75) (-75) (-75) (-75) (-75) (-75) (-75) (-75) (-75) (-75) (-75) (-75) (-75) (-75) (-75) (-75) (-75) (-75) (-75) (-75) (-75) (-75) (-75) (-75)
                (-75) (-75) (-75) (-75) (-75) (-75) (-75) (-75) (-75) (-75) (-75) (-75) (-75) (-75) (-75) (-75) (-75) (-75) (-75) (-75) (-75) (-75) (-75) (-75) (-75) (-75)
                (-75) (-75) (-75) (-75) (-75) (-75) (-75) (-75) (-75) (-75) (-75) (-75) (-75) (-75) (-75) (-75) (-75) (-75) (-75) (-75) (-75) (-75) (-75) (-75) (-75) (-75)
                (-75) (-75) (-75) (-75) (-75) (-75) (-75) (-75) (-75) (-75) (-75) (-75) (-75) (-75) (-75) (-75) (-75) (-75) (-75) (-75) (-75) (-75) (-75) (-75) (-75) (-75)
                (-75) (-75) (-75) (-75) (-75) (-75) (-75) (-75) (-75) (-75) (-75) (-75) (-75) (-75) (-75) (-75) (-75) (-75) (-75) (-75) (-75) (-75) (-75) (-75) (-75) (-75)
                (-75) (-75) (-75) (-75) (-75) (-75) (-75) (-75) (-75) (-75) (-75) (-75) (-75) (-75) (-75) (-75) (-75) (-75) (-75) (-75) (-75) (-75) (-75) (-75) (-75) (-75)
                (-75) (-75) (-75) (-75) (-75) (-75) (-75) (-75) (-75) (-75) (-75) (-75) (-75) (-75) (-75) (-75) (-75) (-75) (-75) (-75) (-75) (-75) (-75) (-75) (-75) (-75)
                (-75) (-75) (-75) (-75) (-75) (-75) (-75) (-75) (-75) (-75) (-75) (-75) (-75) (-75) (-75) (-75) (-75) (-75) (-75) (-75) (-75) (-75) (-75) (-75) (-75) (-75)
                (-75) (-75) (-75) (-75) (-75) (-75) (-75) (-75) (-75) (-75) (-75) (-75) (-75) (-75) (-75) (-75) (-75) (-75) (-75) (-75) (-75) (-75) (-75) (-75) (-75) (-75)
                (-75) (-75) (-75) (-75) (-75) (-75) (-75) (-75) (-75) (-75) (-75) (-75) (-75) (-75) (-75) (-75) (-75) (-75) (-75) (-75) (-75) (-75) (-75) (-75) (-75) (-75)
                (-75) (-75) (-75) (-75) (-75) (-75) (-75) (-75) (-75) (-75) (-75) (-75) (-75) (-75) (-75) (-75) (-75) (-75) (-75) (-75) (-75) (-75) (-75) (-75) (-75) (-75)
                (-75) (-75) (-75) (-75) (-75) (-75) (-75) (-75) (-75) (-75) (-75) (-75) (-75) (-75) (-75) (-75) (-75) (-75) (-75) (-75) (-75) (-75) (-75) (-75) (-75) (-75)
                (-75) (-75) (-75) (-75) (-75) (-75) (-75) (-75) (-75) (-75) (-75) (-75) (-75) (-75) (-75) (-75) (-75) (-75) (-75) (-75) (-75) (-75) (-75) (-75) (-75) (-75)
                (-75) (-75) (-75) (-75) (-75) (-75) (-75) (-75) (-75) (-75) (-75) (-75) (-75) (-75) (-75) (-75) (-75) (-75) (-75) (-75) (-75) (-75) (-75) (-75) (-75) (-75)
                (-75) (-75) (-75) (-75) (-75) (-75) (-75) (-75) (-75) (-75) (-75) (-75) (-75) (-75) (-75) (-75) (-75) (-75) (-75) (-75) (-75) (-75) (-75) (-75) (-75) (-75)
                (-75) (-75) (-75)>;

            /* FDM config */
            FDM_X_Channel = <2>;

            PS_Config_Lmt_FDM_Rawdata_P = <
                900 900
                900 900
                900 900
                900 900
                900 900
                900 900
                900 900
                900 900
                900 900
                900 900
                900 900
                900 900
                900 900
                900 900
                900 900
                900 900
                900 900
                900 900
                900 900
                900 900
                900 900
                900 900
                900 900
                900 900
                900 900
                900 900
                900 900
                900 900
                900 900
                900 900
                900 900
                900 900
                900 900
                900 900
                900 900
                900 900>;

            PS_Config_Lmt_FDM_Rawdata_N = <
                50 50
                50 50
                50 50
                50 50
                50 50
                50 50
                50 50
                50 50
                50 50
                50 50
                50 50
                50 50
                50 50
                50 50
                50 50
                50 50
                50 50
                50 50
                50 50
                50 50
                50 50
                50 50
                50 50
                50 50
                50 50
                50 50
                50 50
                50 50
                50 50
                50 50
                50 50
                50 50
                50 50
                50 50
                50 50
                50 50>;

            PS_Config_FDM_Noise_Test_Frame = <50>;
            PS_Config_Lmt_FDM_Diff_P = <
                180 180
                180 180
                180 180
                180 180
                180 180
                180 180
                180 180
                180 180
                180 180
                180 180
                180 180
                180 180
                180 180
                180 180
                180 180
                180 180
                180 180
                180 180
                180 180
                180 180
                180 180
                180 180
                180 180
                180 180
                180 180
                180 180
                180 180
                180 180
                180 180
                180 180
                180 180
                180 180
                180 180
                180 180
                180 180
                180 180>;

            PS_Config_Lmt_FDM_Diff_N = <
                (-180) (-180)
                (-180) (-180)
                (-180) (-180)
                (-180) (-180)
                (-180) (-180)
                (-180) (-180)
                (-180) (-180)
                (-180) (-180)
                (-180) (-180)
                (-180) (-180)
                (-180) (-180)
                (-180) (-180)
                (-180) (-180)
                (-180) (-180)
                (-180) (-180)
                (-180) (-180)
                (-180) (-180)
                (-180) (-180)
                (-180) (-180)
                (-180) (-180)
                (-180) (-180)
                (-180) (-180)
                (-180) (-180)
                (-180) (-180)
                (-180) (-180)
                (-180) (-180)
                (-180) (-180)
                (-180) (-180)
                (-180) (-180)
                (-180) (-180)
                (-180) (-180)
                (-180) (-180)
                (-180) (-180)
                (-180) (-180)
                (-180) (-180)
                (-180) (-180)>;
        };
    };
    /*Tab A9 code for AX6739A-2660 by zhawei at 20230811 end*/
};

/*Tab A9 code for AX6739A-6 by wenghailong at 20230418 end*/
/* TOUCH end */
